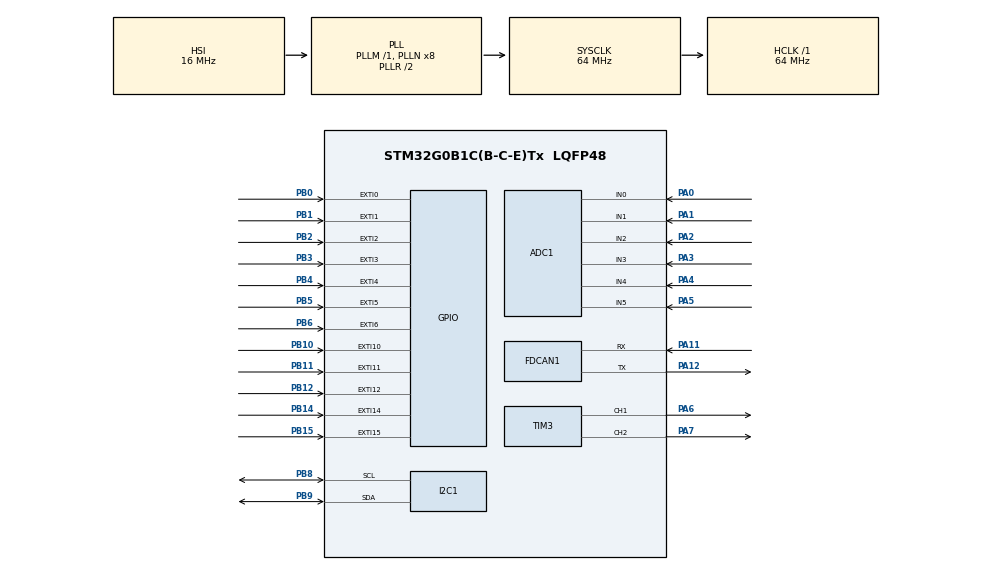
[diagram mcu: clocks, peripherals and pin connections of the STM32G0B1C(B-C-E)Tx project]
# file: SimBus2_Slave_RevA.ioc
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ADC1.Channel-2\#ChannelRegularConversion=ADC_CHANNEL_0
ADC1.Channel-3\#ChannelRegularConversion=ADC_CHANNEL_0
ADC1.Channel-4\#ChannelRegularConversion=ADC_CHANNEL_0
ADC1.Channel-5\#ChannelRegularConversion=ADC_CHANNEL_0
ADC1.Channel-6\#ChannelRegularConversion=ADC_CHANNEL_0
ADC1.Channel-7\#ChannelRegularConversion=ADC_CHANNEL_0
ADC1.ContinuousConvMode=ENABLE
ADC1.DMAContinuousRequests=ENABLE
ADC1.EOCSelection=ADC_EOC_SEQ_CONV
ADC1.NbrOfConversion=6
ADC1.NbrOfConversionFlag=1
ADC1.Rank-2\#ChannelRegularConversion=1
ADC1.Rank-3\#ChannelRegularConversion=2
ADC1.Rank-4\#ChannelRegularConversion=3
ADC1.Rank-5\#ChannelRegularConversion=4
ADC1.Rank-6\#ChannelRegularConversion=5
ADC1.Rank-7\#ChannelRegularConversion=6
ADC1.SamplingTime-2\#ChannelRegularConversion=ADC_SAMPLINGTIME_COMMON_1
ADC1.SamplingTime-3\#ChannelRegularConversion=ADC_SAMPLINGTIME_COMMON_1
ADC1.SamplingTime-4\#ChannelRegularConversion=ADC_SAMPLINGTIME_COMMON_1
ADC1.SamplingTime-5\#ChannelRegularConversion=ADC_SAMPLINGTIME_COMMON_1
ADC1.SamplingTime-6\#ChannelRegularConversion=ADC_SAMPLINGTIME_COMMON_1
ADC1.SamplingTime-7\#ChannelRegularConversion=ADC_SAMPLINGTIME_COMMON_1
ADC1.SelectedChannel=ADC_CHANNEL_0|ADC_CHANNEL_1|ADC_CHANNEL_2|ADC_CHANNEL_3|ADC_CHANNEL_4|ADC_CHANNEL_5
ADC1.master=1
Dma.ADC1.0.Direction=DMA_PERIPH_TO_MEMORY
Dma.ADC1.0.EventEnable=DISABLE
Dma.ADC1.0.Instance=DMA1_Channel1
Dma.ADC1.0.MemDataAlignment=DMA_MDATAALIGN_HALFWORD
Dma.ADC1.0.MemInc=DMA_MINC_ENABLE
Dma.ADC1.0.Mode=DMA_CIRCULAR
Dma.ADC1.0.PeriphDataAlignment=DMA_PDATAALIGN_HALFWORD
Dma.ADC1.0.PeriphInc=DMA_PINC_DISABLE
Dma.ADC1.0.Polarity=HAL_DMAMUX_REQ_GEN_RISING
Dma.ADC1.0.Priority=DMA_PRIORITY_MEDIUM
Dma.ADC1.0.RequestNumber=1
Dma.ADC1.0.SignalID=NONE
Dma.ADC1.0.SyncEnable=DISABLE
Dma.ADC1.0.SyncPolarity=HAL_DMAMUX_SYNC_NO_EVENT
Dma.ADC1.0.SyncRequestNumber=1
Dma.ADC1.0.SyncSignalID=NONE
Dma.Request0=ADC1
FDCAN1.AutoRetransmission=ENABLE
FDCAN1.CalculateBaudRateNominal=1333333
FDCAN1.CalculateTimeBitNominal=750
FDCAN1.CalculateTimeQuantumNominal=250.0
I2C1.Timing=0x10B17DB5
Mcu.Family=STM32G0
Mcu.Name=STM32G0B1C(B-C-E)Tx
Mcu.Package=LQFP48
NVIC.DMA1_Channel1_IRQn=true\:0\:0\:false\:false\:true\:false\:true\:true
NVIC.EXTI0_1_IRQn=true\:0\:0\:false\:false\:true\:true\:true\:true
NVIC.EXTI2_3_IRQn=true\:0\:0\:false\:false\:true\:true\:true\:true
NVIC.EXTI4_15_IRQn=true\:0\:0\:false\:false\:true\:true\:true\:true
NVIC.TIM16_FDCAN_IT0_IRQn=true\:0\:0\:false\:false\:true\:true\:true\:true
NVIC.TIM17_FDCAN_IT1_IRQn=true\:0\:0\:false\:false\:true\:true\:true\:true
PA0.Mode=IN0
PA0.Signal=ADC1_IN0
PA1.Mode=IN1
PA1.Signal=ADC1_IN1
PA11\ [PA9].Mode=FDCAN_Activate
PA11\ [PA9].Signal=FDCAN1_RX
PA12\ [PA10].Mode=FDCAN_Activate
PA12\ [PA10].Signal=FDCAN1_TX
PA13.Mode=Serial_Wire
PA13.Signal=SYS_SWDIO
PA14-BOOT0.Mode=Serial_Wire
PA14-BOOT0.Signal=SYS_SWCLK
PA2.Mode=IN2
PA2.Signal=ADC1_IN2
PA3.Mode=IN3
PA3.Signal=ADC1_IN3
PA4.Mode=IN4
PA4.Signal=ADC1_IN4
PA5.Mode=IN5
PA5.Signal=ADC1_IN5
PA6.Signal=S_TIM3_CH1
PA7.Signal=S_TIM3_CH2
PB0.Signal=GPXTI0
PB1.Signal=GPXTI1
PB10.Signal=GPXTI10
PB11.Signal=GPXTI11
PB12.Signal=GPXTI12
PB14.Signal=GPXTI14
PB15.Signal=GPXTI15
PB2.Signal=GPXTI2
PB3.Signal=GPXTI3
PB4.Signal=GPXTI4
PB5.Signal=GPXTI5
PB6.Signal=GPXTI6
PB8.Mode=I2C
PB8.Signal=I2C1_SCL
PB9.Mode=I2C
PB9.Signal=I2C1_SDA
ProjectManager.HeapSize=0x200
ProjectManager.StackSize=0x400
ProjectManager.TargetToolchain=STM32CubeIDE
RCC.ADCFreq_Value=64000000
RCC.AHBFreq_Value=64000000
RCC.CortexFreq_Value=64000000
RCC.EXTERNAL_CLOCK_VALUE=48000
RCC.HCLKFreq_Value=64000000
RCC.HSE_VALUE=8000000
RCC.HSI48_VALUE=48000000
RCC.HSI_VALUE=16000000
RCC.LSE_VALUE=32768
RCC.SYSCLKFreq_VALUE=64000000
RCC.SYSCLKSource=RCC_SYSCLKSOURCE_PLLCLK
RCC.USBFreq_Value=48000000
RCC.VCOOutputFreq_Value=128000000
SH.S_TIM3_CH1.0=TIM3_CH1,PWM Generation1 CH1
SH.S_TIM3_CH2.0=TIM3_CH2,PWM Generation2 CH2
TIM3.Channel-PWM\ Generation1\ CH1=TIM_CHANNEL_1
TIM3.Channel-PWM\ Generation2\ CH2=TIM_CHANNEL_2
VP_SYS_VS_DBSignals.Mode=DisableDeadBatterySignals
board=custom

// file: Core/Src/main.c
/* USER CODE BEGIN Header */
/**
  ******************************************************************************
  * @file           : main.c
  * @brief          : Main program body
  ******************************************************************************
  * @attention
  *
  * Copyright (c) 2026 STMicroelectronics.
  * All rights reserved.
  *
  * This software is licensed under terms that can be found in the LICENSE file
  * in the root directory of this software component.
  * If no LICENSE file comes with this software, it is provided AS-IS.
  *
  ******************************************************************************
  */
/* USER CODE END Header */
#include "main.h"
#include "adc.h"
#include "dma.h"
#include "fdcan.h"
#include "i2c.h"
#include "tim.h"
#include "gpio.h"

/* USER CODE BEGIN Includes */
#include "app.h"
#include "encoder.h"
/* USER CODE END Includes */

void SystemClock_Config(void);

/* USER CODE BEGIN 0 */
/* NIC TU NIE DODAJEMY dla EXTI CALLBACK – ma być tylko w stm32g0xx_it.c */
/* USER CODE END 0 */

int main(void)
{

  /* MCU Configuration--------------------------------------------------------*/

  /* Reset of all peripherals, Initializes the Flash interface and the Systick. */
  HAL_Init();

  /* Configure the system clock */
  SystemClock_Config();

  /* Initialize all configured peripherals */
  MX_GPIO_Init();
  MX_DMA_Init();
  MX_ADC1_Init();
  MX_FDCAN1_Init();
  MX_I2C1_Init();
  MX_TIM3_Init();
  /* USER CODE BEGIN 2 */
  Encoder_Init();
  App_Init();
  /* USER CODE END 2 */

  /* Infinite loop */
  /* USER CODE BEGIN WHILE */
  while (1)
  {
    App_Run();

    /* opcjonalnie: oddaj CPU między eventami (bezpieczne, bo budzi nas SysTick/IRQ) */
    __WFI();
  }
    /* USER CODE END WHILE */

}

void SystemClock_Config(void)
{
  RCC_OscInitTypeDef RCC_OscInitStruct = {0};
  RCC_ClkInitTypeDef RCC_ClkInitStruct = {0};

  /** Configure the main internal regulator output voltage
  */
  HAL_PWREx_ControlVoltageScaling(PWR_REGULATOR_VOLTAGE_SCALE1);

  /** Initializes the RCC Oscillators according to the specified parameters
  * in the RCC_OscInitTypeDef structure.
  */
  RCC_OscInitStruct.OscillatorType = RCC_OSCILLATORTYPE_HSI;
  RCC_OscInitStruct.HSIState = RCC_HSI_ON;
  RCC_OscInitStruct.HSIDiv = RCC_HSI_DIV1;
  RCC_OscInitStruct.HSICalibrationValue = RCC_HSICALIBRATION_DEFAULT;
  RCC_OscInitStruct.PLL.PLLState = RCC_PLL_ON;
  RCC_OscInitStruct.PLL.PLLSource = RCC_PLLSOURCE_HSI;
  RCC_OscInitStruct.PLL.PLLM = RCC_PLLM_DIV1;
  RCC_OscInitStruct.PLL.PLLN = 8;
  RCC_OscInitStruct.PLL.PLLP = RCC_PLLP_DIV2;
  RCC_OscInitStruct.PLL.PLLQ = RCC_PLLQ_DIV2;
  RCC_OscInitStruct.PLL.PLLR = RCC_PLLR_DIV2;
  if (HAL_RCC_OscConfig(&RCC_OscInitStruct) != HAL_OK)
  {
    Error_Handler();
  }

  /** Initializes the CPU, AHB and APB buses clocks
  */
  RCC_ClkInitStruct.ClockType = RCC_CLOCKTYPE_HCLK|RCC_CLOCKTYPE_SYSCLK
                              |RCC_CLOCKTYPE_PCLK1;
  RCC_ClkInitStruct.SYSCLKSource = RCC_SYSCLKSOURCE_PLLCLK;
  RCC_ClkInitStruct.AHBCLKDivider = RCC_SYSCLK_DIV1;
  RCC_ClkInitStruct.APB1CLKDivider = RCC_HCLK_DIV1;

  if (HAL_RCC_ClockConfig(&RCC_ClkInitStruct, FLASH_LATENCY_2) != HAL_OK)
  {
    Error_Handler();
  }
}

void Error_Handler(void)
{
  __disable_irq();
  while (1)
  {
  }
}
